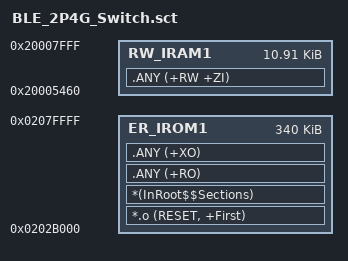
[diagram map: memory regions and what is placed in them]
; *************************************************************
; *** Scatter-Loading Description File generated by uVision ***
; *************************************************************

LR_IROM1 0x0202B000 0x00055000  {    ; load region size_region
  ER_IROM1 0x0202B000 0x00055000  {  ; load address = execution address
   *.o (RESET, +First)
   *(InRoot$$Sections)
   .ANY (+RO)
   .ANY (+XO)
  }
  RW_IRAM1 0x20005460 0x00002BA0  {  ; RW data
   .ANY (+RW +ZI)
  }
}

